AUTOSAR XML (schema 4-2-2)
package /Components
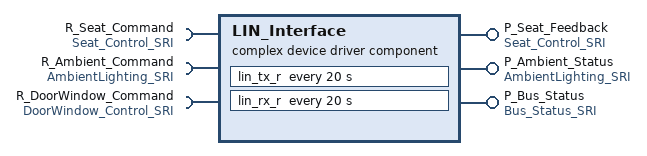
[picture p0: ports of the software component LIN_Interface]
  complex device driver sw component type LIN_Interface
    provide port P_Seat_Feedback: provided-interface=Seat_Control_SRI
    provide port P_Ambient_Status: provided-interface=AmbientLighting_SRI
    provide port P_Bus_Status: provided-interface=Bus_Status_SRI
    require port R_Seat_Command: required-interface=Seat_Control_SRI
    require port R_Ambient_Command: required-interface=AmbientLighting_SRI
    require port R_DoorWindow_Command: required-interface=DoorWindow_Control_SRI
    behavior LIN_Interface_InternalBehavior
      init event LIN_Init: start-on-event=lin_tx_r
      timing event LIN_Main_Schedule_Tx: start-on-event=lin_tx_r, period=20
      timing event LIN_Main_Schedule_Rx: start-on-event=lin_rx_r, period=20
      runnable lin_tx_r: minimum-start-interval=20
        data-receive-point-by-arguments:
          6 x access:
            rx_seat_position_cmd_access: accessed-variable=R_Seat_Command.seat_position_cmd
            rx_seat_heater_cmd_access: accessed-variable=R_Seat_Command.seat_heater_cmd
            rx_ambient_color_cmd_access: accessed-variable=R_Ambient_Command.ambient_color_cmd
            rx_ambient_brightness_cmd_access: accessed-variable=R_Ambient_Command.ambient_brightness_cmd
            rx_door_lock_cmd_access: accessed-variable=R_DoorWindow_Command.door_lock_cmd
            rx_window_move_cmd_access: accessed-variable=R_DoorWindow_Command.window_move_cmd
        data-send-points:
          access tx_bus_online_access: accessed-variable=P_Bus_Status.bus_online
          access tx_bus_error_count_access: accessed-variable=P_Bus_Status.bus_error_count
          access tx_bus_load_access: accessed-variable=P_Bus_Status.bus_load
      runnable lin_rx_r: minimum-start-interval=20
        data-send-points:
          access tx_seat_position_feedback_access: accessed-variable=P_Seat_Feedback.seat_position_feedback
          access tx_seat_heater_status_access: accessed-variable=P_Seat_Feedback.seat_heater_status
          access tx_ambient_status_access: accessed-variable=P_Ambient_Status.ambient_status
